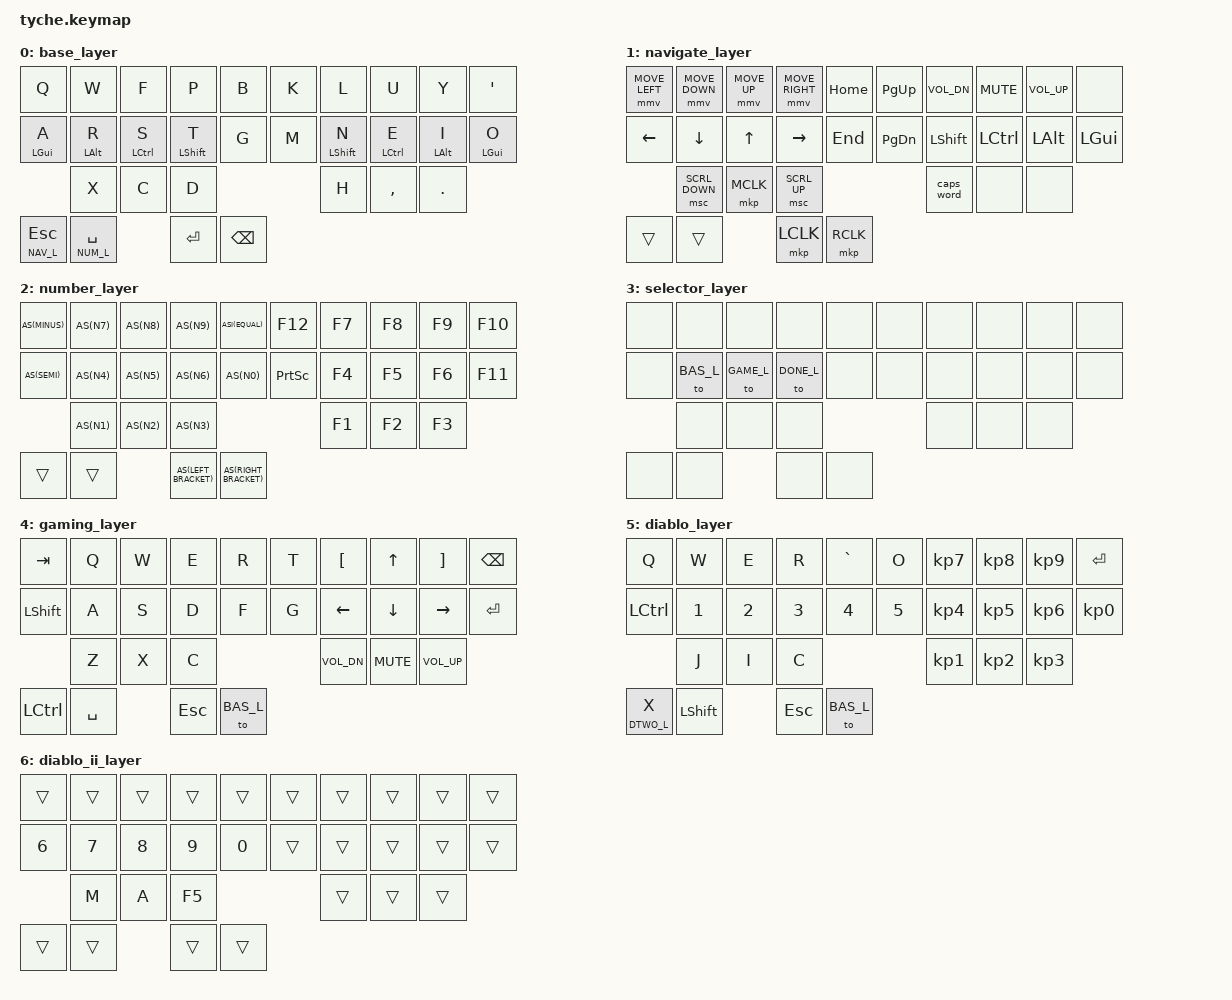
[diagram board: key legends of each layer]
/*
 * Copyright (c) 2024 Rooks
 * 
 * SPDX-License-Identifier: MIT
 */

#include <behaviors.dtsi>
#include <dt-bindings/zmk/keys.h>
#include <dt-bindings/zmk/pointing.h>
#include <dt-bindings/zmk/bt.h>
#include <dt-bindings/zmk/outputs.h>

#define AS(keycode) &as LS(keycode) keycode     // Autoshift Macro
#define ASI(keycode) &as keycode LS(keycode)     // Autoshift Macro inverted
#define BAS_L 0
#define NAV_L 1
#define NUM_L 2
#define SEL_L 3
#define GAME_L 4
#define DONE_L 5
#define DTWO_L 6

#define KEYS_L 0 1 2 3 4    10 11 12 13 14    20 21 22
#define KEYS_R 5 6 7 8 9    15 16 17 18 19    23 24 25

#define THUMBS 26 27 28 29

// Using layer taps on thumbs, having quick tap as well helps w/ repeating space/backspace
&lt { quick_tap_ms = <200>; };

#define BT(n) BT_SEL n

/ {
    behaviors {
        hml: hrm_left {
            compatible = "zmk,behavior-hold-tap";
            #binding-cells = <2>;
            flavor = "balanced";
            tapping-term-ms = <200>;
            quick-tap-ms = <150>;
            bindings = <&kp>, <&kp>;
            hold-trigger-key-positions = <KEYS_R THUMBS>;
            hold-trigger-on-release;
        };
        hmr: hrm_right {
            compatible = "zmk,behavior-hold-tap";
            #binding-cells = <2>;
            flavor = "balanced";
            tapping-term-ms = <200>;
            quick-tap-ms = <150>;
            bindings = <&kp>, <&kp>;
            hold-trigger-key-positions = <KEYS_L THUMBS>;
            hold-trigger-on-release;
        };
        as: auto_shift {
            compatible = "zmk,behavior-hold-tap";
            #binding-cells = <2>;
            tapping_term_ms = <200>;
            quick_tap_ms = <100>;
            flavor = "tap-preferred";
            bindings = <&kp>, <&kp>;
        };
    };

/*
** 0  1  2  3  4       5  6  7  8  9
** 10 11 12 13 14      15 16 17 18 19
**    20 21 22            23 24 25
**          26 27      28 29
**
     */

    keymap {
        compatible = "zmk,keymap";

        base_layer {
            bindings = <
                &kp Q         &kp W         &kp F          &kp P           &kp B       &kp K      &kp L          &kp U          &kp Y         &kp QUOT
                &hml LGUI A   &hml LALT R   &hml LCTRL S   &hml LSHFT T    &kp G       &kp M      &hmr LSHFT N   &hmr LCTRL E   &hmr LALT I   &hmr LGUI O   
                              &kp X         &kp C          &kp D                                  &kp H          &kp COMMA      &kp DOT
                &lt NAV_L ESC &lt NUM_L SPACE              &kp RET    &kp BKSP
                >;
        };
        navigate_layer {
            bindings = <
                &mmv MOVE_LEFT &mmv MOVE_DOWN &mmv MOVE_UP &mmv MOVE_RIGHT &kp HOME     &kp PG_UP    &kp C_VOL_DN  &kp C_MUTE &kp C_VOL_UP &none
                &kp LEFT       &kp DOWN       &kp UP       &kp RIGHT       &kp END      &kp PG_DN    &kp LSHFT     &kp LCTRL  &kp LALT     &kp LGUI
                               &msc SCRL_DOWN &mkp MCLK    &msc SCRL_UP                              &caps_word    &none      &none
                                              &trans       &trans          &mkp LCLK &mkp RCLK
                >;
        };

        number_layer {
            bindings = <
                AS(MINUS) AS(N7) AS(N8) AS(N9) ASI(EQUAL)  &kp F12 &kp F7 &kp F8 &kp F9 &kp F10
                AS(SEMI)  AS(N4) AS(N5) AS(N6) AS(N0)     &kp PSCRN &kp F4 &kp F5 &kp F6 &kp F11
                          AS(N1) AS(N2) AS(N3)                      &kp F1 &kp F2 &kp F3
                &trans &trans AS(LEFT_BRACKET) AS(RIGHT_BRACKET)
                >;
        };

        selector_layer {
            bindings = <
                &none &none &none &none &none &none &none &none &none &none
                &none &to BAS_L &to GAME_L &to DONE_L &none &none &none &none &none &none
                       &none &none &none               &none &none &none
                &none &none        &none &none
                >;
        };

        gaming_layer {
            bindings = <
                &kp TAB &kp Q &kp W &kp E &kp R       &kp T &kp LEFT_BRACKET &kp UP   &kp RIGHT_BRACKET &kp BACKSPACE
                &kp LSHIFT &kp A &kp S &kp D &kp F       &kp G &kp LEFT         &kp DOWN &kp RIGHT         &kp RETURN
                           &kp Z &kp X &kp C                   &kp C_VOL_DN &kp C_MUTE &kp C_VOL_UP
                &kp LCTRL  &kp SPACE &kp ESC &to BAS_L
                >;
        };

        diablo_layer {
            bindings = <
                &kp Q &kp W &kp E &kp R &kp GRAVE       &kp O &kp KP_N7 &kp KP_N8 &kp KP_N9 &kp RETURN
                &kp LCTRL &kp N1 &kp N2 &kp N3 &kp N4   &kp N5 &kp KP_N4 &kp KP_N5 &kp KP_N6 &kp KP_N0
                          &kp J &kp I &kp C                    &kp KP_N1 &kp KP_N2 &kp KP_N3
                &lt DTWO_L X &kp LSHIFT &kp ESC &to BAS_L
                >;
        };

        diablo_ii_layer {
            bindings = <
                &trans &trans &trans &trans &trans &trans &trans &trans &trans &trans
                &kp N6 &kp N7 &kp N8 &kp N9 &kp N0 &trans &trans &trans &trans &trans
                       &kp M &kp A &kp F5               &trans &trans &trans
                &trans &trans        &trans &trans
                >;
        };
    };

    combos {
        compatible = "zmk,combos";
        combo_del { timeout-ms = <50>; key-positions = <16 18>; bindings = <AS(DEL)>; layers = <BAS_L>; };
        combo_tab { timeout-ms = <50>; key-positions = <11 13>; bindings = <AS(TAB)>; layers = <BAS_L>; };
        combo_grave { timeout-ms = <50>; key-positions = <0 1>; bindings = <ASI(GRAVE)>; layers = <NUM_L>; };

        combo_j { timeout-ms = <50>; key-positions = <2 3>; bindings = <&kp J>; layers = <BAS_L>; };
        combo_v { timeout-ms = <50>; key-positions = <14 22>; bindings = <&kp V>; layers = <BAS_L GAME_L>; };
        combo_z { timeout-ms = <50>; key-positions = <1 2>; bindings = <&kp Z>; layers = <BAS_L>; };
        combo_fslash { timeout-ms = <50>; key-positions = <7 8>; bindings = <AS(SLASH)>; layers = <BAS_L>; };
        combo_bslash { timeout-ms = <50>; key-positions = <28 29>; bindings = <AS(BACKSLASH)>; layers = <NUM_L>; };
        combo_t { timeout-ms = <25>; key-positions = <0 10>; bindings = <&kp T>; layers = <GAME_L>; };
        combo_g { timeout-ms = <25>; key-positions = <4 14>; bindings = <&kp G>; layers = <GAME_L>; };
        combo_b { timeout-ms = <25>; key-positions = <10 20>; bindings = <&kp B>; layers = <GAME_L>; };

        combo_mosel { timeout-ms = <50>; key-positions = <28 29>; bindings = <&mo SEL_L>; layers = <BAS_L>; };
        combo_boot { timeout-ms = <50>; key-positions = <1 8 20 25>; bindings = <&bootloader>; };

    };
};


/*
** 0  1  2  3  4       5  6  7  8  9
** 10 11 12 13 14      15 16 17 18 19
**    20 21 22            23 24 25
**          26 27      28 29
**
     */

// vim: ft=c
